# STM32H533 register map
File version: 1.3
CPU: CM33 r0p0, little endian, MPU, FPU, 4 interrupt priority bits
Registers are 32-bit, read-write, reset 0x0 unless marked. A register's access mark holds for its fields unless they carry their own. Offsets are from the block's base; [hi:lo] are bit positions; {n}, {i} and the like mark numbered series; 'fields as' and 'values as' point back to an identical list.

## RCC (part 2 of 2) — RCC address block description
Base 0x44020C00
Same registers: RCC_S 0x54020C00
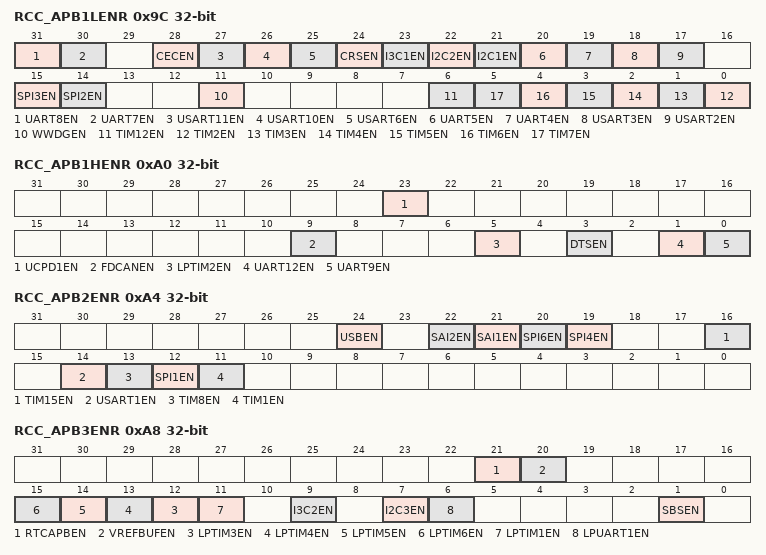
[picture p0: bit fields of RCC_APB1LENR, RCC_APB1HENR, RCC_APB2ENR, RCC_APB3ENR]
0x9C RCC_APB1LENR — RCC APB1 peripheral clock register
  [31] UART8EN — UART8 clock enable
    0=UART8 peripheral clock disabled (default after reset); 1=UART8 peripheral clock enabled
  [30] UART7EN — UART7 clock enable
    0=UART7 peripheral clock disabled (default after reset); 1=UART7 peripheral clock enabled
  [28] CECEN — HDMI-CEC clock enable
    0=HDMI-CEC peripheral clock disabled (default after reset); 1=HDMI-CEC peripheral clock enabled
  [27] USART11EN — USART11 clock enable
    0=USART11 peripheral clock disabled (default after reset); 1=USART11 peripheral clock enabled
  [26] USART10EN — USART10 clock enable
    0=USART10 peripheral clock disabled (default after reset); 1=USART10 peripheral clock enabled
  [25] USART6EN — USART6 clock enable
    0=USART6 peripheral clock disabled (default after reset); 1=USART6 peripheral clock enabled
  [24] CRSEN — CRS clock enable
    0=CRS peripheral clock disabled (default after reset); 1=CRS peripheral clock enabled
  [23] I3C1EN — I3C1 clock enable
    0=I3C1 peripheral clock disabled (default after reset); 1=I3C1 peripheral clock enabled
  [22] I2C2EN — I2C2 clock enable
    0=I2C2 peripheral clock disabled (default after reset); 1=I2C2 peripheral clock enabled
  [21] I2C1EN — I2C1 clock enable
    0=I2C1 peripheral clock disabled (default after reset); 1=I2C1 peripheral clock enabled
  [20] UART5EN — UART5 clock enable
    0=UART5 peripheral clock disabled (default after reset); 1=UART5 peripheral clock enabled
  [19] UART4EN — UART4 clock enable
    0=UART4 peripheral clock disabled (default after reset); 1=UART4 peripheral clock enabled
  [18] USART3EN — USART3 clock enable
    0=USART3 peripheral clock disabled (default after reset); 1=USART3 peripheral clock enabled
  [17] USART2EN — USART2 clock enable
    0=USART2 peripheral clock disabled (default after reset); 1=USART2 peripheral clock enabled
  [15] SPI3EN — SPI3 clock enable
    0=SPI3 peripheral clock disabled (default after reset); 1=SPI3 peripheral clock enabled
  [14] SPI2EN — SPI2 clock enable
    0=SPI2 peripheral clock disabled (default after reset); 1=SPI2 peripheral clock enabled
  [11] WWDGEN — WWDG clock enable
    0=WWDG peripheral clock disabled (default after reset); 1=WWDG peripheral clock enabled
  [6] TIM12EN — TIM12 clock enable
    0=TIM12 peripheral clock disabled (default after reset); 1=TIM12 peripheral clock enabled
  [n-2] TIM{n}EN (n=2..7) — TIM{n} clock enable
    0=TIM{n} peripheral clock disabled (default after reset); 1=TIM{n} peripheral clock enabled
0xA0 RCC_APB1HENR — RCC APB1 peripheral clock register
  [23] UCPD1EN — UCPD1 clock enable
    0=UCPD peripheral clock disabled (default after reset); 1=UCPD peripheral clock enabled
  [9] FDCANEN — FDCAN1 and FDCAN2 peripheral clock enable
    0=FDCAN1 and FDCAN2 peripheral clock disabled (default after reset); 1=FDCAN1 and FDCAN2 peripheral clock enabled
  [5] LPTIM2EN — LPTIM2 clock enable
    0=LPTIM2 peripheral clock disabled (default after reset); 1=LPTIM2 peripheral clock enabled
  [3] DTSEN — DTS clock enable
    0=DTS peripheral clock disabled (default after reset); 1=DTS peripheral clock enabled
  [1] UART12EN — UART12 clock enable
    0=UART12 peripheral clock disabled (default after reset); 1=UART12 peripheral clock enabled
  [0] UART9EN — UART9 clock enable
    0=UART9 peripheral clock disabled (default after reset); 1=resets UART9 peripheral clock enabled
0xA4 RCC_APB2ENR — RCC APB2 peripheral clock register
  [24] USBEN — USB clock enable
    0=USB peripheral clock disabled (default after reset); 1=USB peripheral clock enabled
  [22] SAI2EN — SAI2 clock enable
    0=SAI2 clock disabled; 1=SAI2 clock enabled
  [21] SAI1EN — SAI1 clock enable
    0=SAI1 peripheral clock disabled (default after reset); 1=SAI1 peripheral clock enabled
  [20] SPI6EN — SPI6 clock enable
    0=SPI6 peripheral clock disabled (default after reset); 1=SPI6 peripheral clock enabled
  [19] SPI4EN — SPI4 clock enable
    0=SPI4 peripheral clock disabled (default after reset); 1=SPI4 peripheral clock enabled
  [16] TIM15EN — TIM15 clock enable
    0=TIM15 peripheral clock disabled (default after reset); 1=TIM15 peripheral clock enabled
  [14] USART1EN — USART1 clock enable
    0=USART1 peripheral clock disabled (default after reset); 1=USART1 peripheral clock enabled
  [13] TIM8EN — TIM8 clock enable
    0=TIM8 peripheral clock disabled (default after reset); 1=TIM8 peripheral clock enabled
  [12] SPI1EN — SPI1 clock enable
    0=SPI1 peripheral clock disabled (default after reset); 1=SPI1 peripheral clock enabled
  [11] TIM1EN — TIM1 clock enable
    0=TIM1 peripheral clock disabled (default after reset); 1=TIM1 peripheral clock enabled
0xA8 RCC_APB3ENR — RCC APB3 peripheral clock register
  [21] RTCAPBEN — RTC APB interface clock enable
    0=RTC APB interface clock disabled (default after reset); 1=RTC APB interface clock enabled
  [20] VREFBUFEN — VREFBUF clock enable
    0=VREFBUF peripheral clock disabled (default after reset); 1=VREFBUF peripheral clock enabled
  [n+9] LPTIM{n}EN (n=3..6) — LPTIM{n} clock enable
    0=LPTIM{n} peripheral clock disabled (default after reset); 1=LPTIM{n} peripheral clock enabled
  [11] LPTIM1EN — LPTIM1 clock enable
    0=LPTIM1 peripheral clock disabled (default after reset); 1=LPTIM1 peripheral clock enabled
  [9] I3C2EN — I3C2 clock enable
    0=I3C2 peripheral clock disabled (default after reset); 1=I3C2 peripheral clock enabled
  [7] I2C3EN — I2C3 clock enable
    0=I2C3 peripheral clock disabled (default after reset); 1=I2C3 peripheral clock enabled
  [6] LPUART1EN — LPUART1 clock enable
    0=LPUART1 peripheral clock disabled (default after reset); 1=LPUART1 peripheral clock enabled
  [1] SBSEN — SBS clock enable
    0=SBS peripheral clock disabled (default after reset); 1=SBS peripheral clock enabled
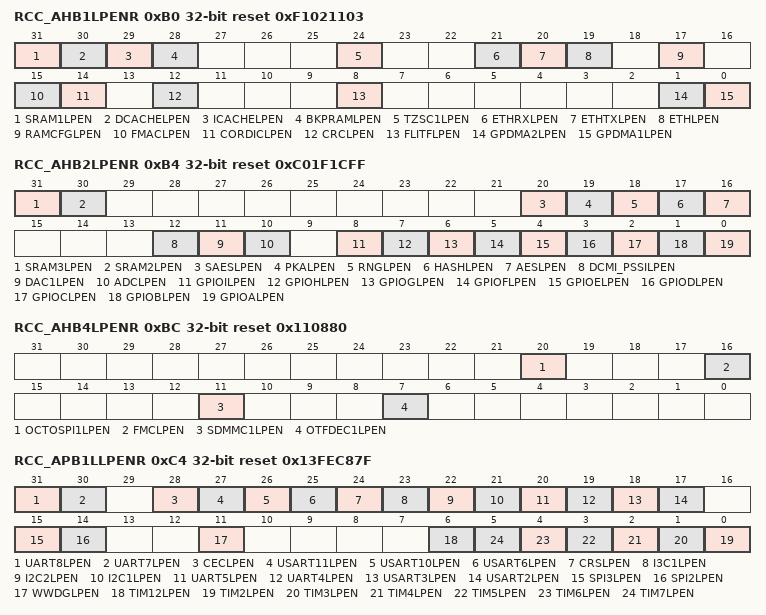
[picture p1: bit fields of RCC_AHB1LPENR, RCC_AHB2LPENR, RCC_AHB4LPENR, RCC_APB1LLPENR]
0xB0 RCC_AHB1LPENR reset 0xF1021103 — RCC AHB1 sleep clock register
  [31] SRAM1LPEN — SRAM1 clock enable during Sleep mode
    0=SRAM1 peripheral clock disabled during Sleep mode; 1=SRAM1 peripheral clock enabled during Sleep mode (default after reset)
  [30] DCACHELPEN — DCACHE clock enable during Sleep mode
    0=DCACHE peripheral clock disabled during Sleep mode; 1=DCACHE peripheral clock enabled during Sleep mode (default after reset)
  [29] ICACHELPEN — ICACHE clock enable during Sleep mode
    0=ICACHE peripheral clock disabled during Sleep mode; 1=ICACHE peripheral clock enabled during Sleep mode (default after reset)
  [28] BKPRAMLPEN — BKPRAM clock enable during Sleep mode
    0=BKPRAM peripheral clock disabled during Sleep mode; 1=BKPRAM peripheral clock enabled during Sleep mode (default after reset)
  [24] TZSC1LPEN — TZSC1 clock enable during Sleep mode
    0=TZSC1 peripheral clock disabled during Sleep mode; 1=TZSC1 peripheral clock enabled during Sleep mode (default after reset)
  [21] ETHRXLPEN — ETHRX clock enable during Sleep mode
    0=ETHRX clock disabled during Sleep mode; 1=ETHRX clock enabled during Sleep mode (default after reset)
  [20] ETHTXLPEN — ETHTX clock enable during Sleep mode
    0=ETHTX clock disabled during Sleep mode; 1=ETHTX clock enabled during Sleep mode (default after reset)
  [19] ETHLPEN — ETH clock enable during Sleep mode
    0=ETH peripheral clock disabled during Sleep mode; 1=ETH peripheral clock enabled during Sleep mode (default after reset)
  [17] RAMCFGLPEN — RAMCFG clock enable during Sleep mode
    0=RAMCFG peripheral clock disabled during Sleep mode; 1=RAMCFG peripheral clock enabled during Sleep mode (default after reset)
  [15] FMACLPEN — FMAC clock enable during Sleep mode
    0=FMAC peripheral clock disabled during Sleep mode; 1=FMAC peripheral clock enabled during Sleep mode (default after reset)
  [14] CORDICLPEN — CORDIC clock enable during Sleep mode
    0=CORDIC peripheral clock disabled during Sleep mode; 1=CORDIC peripheral clock enabled during Sleep mode (default after reset)
  [12] CRCLPEN — CRC clock enable during Sleep mode
    0=CRC peripheral clock disabled during Sleep mode; 1=CRC peripheral clock enabled during Sleep mode (default after reset)
  [8] FLITFLPEN — Flash interface (FLITF) clock enable during Sleep mode
    0=FLITF peripheral clock disabled during Sleep mode; 1=FLITF peripheral clock enabled during Sleep mode (default after reset)
  [1] GPDMA2LPEN — GPDMA2 clock enable during Sleep mode
    0=GPDMA2 peripheral clock disabled during Sleep mode; 1=GPDMA2 peripheral clock enabled during Sleep mode (default after reset)
  [0] GPDMA1LPEN — GPDMA1 clock enable during Sleep mode
    0=GPDMA1 peripheral clock disabled during Sleep mode; 1=GPDMA1 peripheral clock enabled during Sleep mode (default after reset)
0xB4 RCC_AHB2LPENR reset 0xC01F1CFF — RCC AHB2 sleep clock register
  [31] SRAM3LPEN — SRAM3 clock enable during Sleep mode
    0=SRAM3 peripheral clock disabled during Sleep mode; 1=SRAM3 peripheral clock enabled during Sleep mode (default after reset)
  [30] SRAM2LPEN — SRAM2 clock enable during Sleep mode
    0=SRAM2 peripheral clock disabled during Sleep mode; 1=SRAM2 peripheral clock enabled during Sleep mode (default after reset)
  [20] SAESLPEN — SAES clock enable during Sleep mode
    0=SAES peripheral clock disabled during Sleep mode; 1=SAES peripheral clock enabled during Sleep mode (default after reset)
  [19] PKALPEN — PKA clock enable during Sleep mode
    0=PKA peripheral clock disabled during Sleep mode; 1=PKA peripheral clock enabled during Sleep mode (default after reset)
  [18] RNGLPEN — RNG clock enable during Sleep mode
    0=RNG peripheral clock disabled during Sleep mode; 1=RNG peripheral clock enabled during Sleep mode (default after reset)
  [17] HASHLPEN — HASH clock enable during Sleep mode
    0=HASH peripheral clock disabled during Sleep mode; 1=HASH peripheral clock enabled during Sleep mode (default after reset)
  [16] AESLPEN — AES clock enable during Sleep mode
    0=AES peripheral clock disabled during Sleep mode; 1=AES peripheral clock enabled during Sleep mode (default after reset)
  [12] DCMI_PSSILPEN — digital camera interface clock enable during Sleep mode (DCMI or PSSI depending which interface is active)
    0=DCMI/PSSI peripheral clock disabled during Sleep mode; 1=DCMI/PSSI peripheral clock enabled during Sleep mode (default after reset)
  [11] DAC1LPEN — DAC clock enable during Sleep mode
    0=DAC peripheral clock disabled during Sleep mode; 1=DAC peripheral clock enabled during Sleep mode (default after reset)
  [10] ADCLPEN — ADC1 and 2 peripherals clock enable during Sleep mode
    0=ADC1 and 2 peripherals clock disabled during Sleep mode; 1=ADC1 and 2 peripherals clock enabled during Sleep mode (default after reset)
  [8] GPIOILPEN — GPIOI clock enable during Sleep mode
    0=GPIOI peripheral clock disabled during Sleep mode; 1=GPIOI peripheral clock enabled during Sleep mode (default after reset)
  [7] GPIOHLPEN — GPIOH clock enable during Sleep mode
    0=GPIOH peripheral clock disabled during Sleep mode; 1=GPIOH peripheral clock enabled during Sleep mode (default after reset)
  [6] GPIOGLPEN — GPIOG clock enable during Sleep mode
    0=GPIOG peripheral clock disabled during Sleep mode; 1=GPIOG peripheral clock enabled during Sleep mode (default after reset)
  [5] GPIOFLPEN — GPIOF clock enable during Sleep mode
    0=GPIOF peripheral clock disabled during Sleep mode; 1=GPIOF peripheral clock enabled during Sleep mode (default after reset)
  [4] GPIOELPEN — GPIOE clock enable during Sleep mode
    0=GPIOE peripheral clock disabled during Sleep mode; 1=GPIOE peripheral clock enabled during Sleep mode (default after reset)
  [3] GPIODLPEN — GPIOD clock enable during Sleep mode
    0=GPIOD peripheral clock disabled during Sleep mode; 1=GPIOD peripheral clock enabled during Sleep mode (default after reset)
  [2] GPIOCLPEN — GPIOC clock enable during Sleep mode
    0=GPIOC peripheral clock disabled during Sleep mode; 1=GPIOC peripheral clock enabled during Sleep mode (default after reset)
  [1] GPIOBLPEN — GPIOB clock enable during Sleep mode
    0=GPIOB peripheral clock disabled during Sleep mode; 1=GPIOB peripheral clock enabled during Sleep mode (default after reset)
  [0] GPIOALPEN — GPIOA clock enable during Sleep mode
    0=GPIOA peripheral clock disabled during Sleep mode; 1=GPIOA peripheral clock enabled during Sleep mode (default after reset)
0xBC RCC_AHB4LPENR reset 0x110880 — RCC AHB4 sleep clock register
  [20] OCTOSPI1LPEN — OCTOSPI1 clock enable during Sleep mode
    0=OCTOSPI1 peripheral clock disabled during Sleep mode; 1=OCTOSPI1 peripheral clock enabled during Sleep mode (default after reset)
  [16] FMCLPEN — FMC clock enable during Sleep mode
    0=FMC peripheral clock disabled during Sleep mode; 1=FMC peripheral clock enabled during Sleep mode (default after reset)
  [11] SDMMC1LPEN — SDMMC1 and SDMMC1 delay peripheral clock enable during Sleep mode
    0=SDMMC1 and SDMMC1 delay peripherals clock disabled during Sleep mode; 1=SDMMC1 and SDMMC1 delay peripherals clock enabled during Sleep mode (default after reset)
  [7] OTFDEC1LPEN — OTFDEC1 clock enable during Sleep mode
    0=OTFDEC1 peripheral clock disabled during Sleep mode; 1=OTFDEC1 peripheral clock enabled during Sleep mode (default after reset)
0xC4 RCC_APB1LLPENR reset 0x13FEC87F — RCC APB1 sleep clock register
  [31] UART8LPEN — UART8 clock enable during Sleep mode
    0=UART8 peripheral clock disabled during Sleep mode; 1=UART8 peripheral clock enabled during Sleep mode (default after reset)
  [30] UART7LPEN — UART7 clock enable during Sleep mode
    0=UART7 peripheral clock disabled during Sleep mode; 1=UART7 peripheral clock enabled during Sleep mode (default after reset)
  [28] CECLPEN — HDMI-CEC clock enable during Sleep mode
    0=HDMI-CEC peripheral clock disabled during Sleep mode; 1=HDMI-CEC peripheral clock enabled during Sleep mode (default after reset)
  [27] USART11LPEN — USART11 clock enable during Sleep mode
    0=USART11 peripheral clock disabled during Sleep mode; 1=USART11 peripheral clock enabled during Sleep mode (default after reset)
  [26] USART10LPEN — USART10 clock enable during Sleep mode
    0=USART10 peripheral clock disabled during Sleep mode; 1=USART10 peripheral clock enabled during Sleep mode (default after reset)
  [25] USART6LPEN — USART6 clock enable during Sleep mode
    0=USART6 peripheral clock disabled during Sleep mode; 1=USART6 peripheral clock enabled during Sleep mode (default after reset)
  [24] CRSLPEN — CRS clock enable during Sleep mode
    0=CRS peripheral clock disabled during Sleep mode; 1=CRS peripheral clock enabled during Sleep mode (default after reset)
  [23] I3C1LPEN — I3C1 clock enable during Sleep mode
    0=I3C1 peripheral clock disabled during Sleep mode; 1=I3C1 peripheral clock enabled during Sleep mode (default after reset)
  [22] I2C2LPEN — I2C2 clock enable during Sleep mode
    0=I2C2 peripheral clock disabled during Sleep mode; 1=I2C2 peripheral clock enabled during Sleep mode (default after reset)
  [21] I2C1LPEN — I2C1 clock enable during Sleep mode
    0=I2C1 peripheral clock disabled during Sleep mode; 1=I2C1 peripheral clock enabled during Sleep mode (default after reset)
  [20] UART5LPEN — UART5 clock enable during Sleep mode
    0=UART5 peripheral clock disabled during Sleep mode; 1=UART5 peripheral clock enabled during Sleep mode (default after reset)
  [19] UART4LPEN — UART4 clock enable during Sleep mode
    0=UART4 peripheral clock disabled during Sleep mode; 1=UART4 peripheral clock enabled during Sleep mode (default after reset)
  [18] USART3LPEN — USART3 clock enable during Sleep mode
    0=USART3 peripheral clock disabled during Sleep mode; 1=USART3 peripheral clock enabled during Sleep mode (default after reset)
  [17] USART2LPEN — USART2 clock enable during Sleep mode
    0=USART2 peripheral clock disabled during Sleep mode; 1=USART2 peripheral clock enabled during Sleep mode (default after reset)
  [15] SPI3LPEN — SPI3 clock enable during Sleep mode
    0=SPI3 peripheral clock disabled during Sleep mode; 1=SPI3 peripheral clock enabled during Sleep mode (default after reset)
  [14] SPI2LPEN — SPI2 clock enable during Sleep mode
    0=SPI2 peripheral clock disabled during Sleep mode; 1=SPI2 peripheral clock enabled during Sleep mode (default after reset)
  [11] WWDGLPEN — WWDG clock enable during Sleep mode
    0=WWDG peripheral clock disabled during Sleep mode; 1=WWDG peripheral clock enabled during Sleep mode (default after reset)
  [6] TIM12LPEN — TIM12 clock enable during Sleep mode
    0=TIM12 peripheral clock disabled during Sleep mode; 1=TIM12 peripheral clock enabled during Sleep mode (default after reset)
  [n-2] TIM{n}LPEN (n=2..7) — TIM{n} clock enable during Sleep mode
    0=TIM{n} peripheral clock disabled during Sleep mode; 1=TIM{n} peripheral clock enabled during Sleep mode (default after reset)
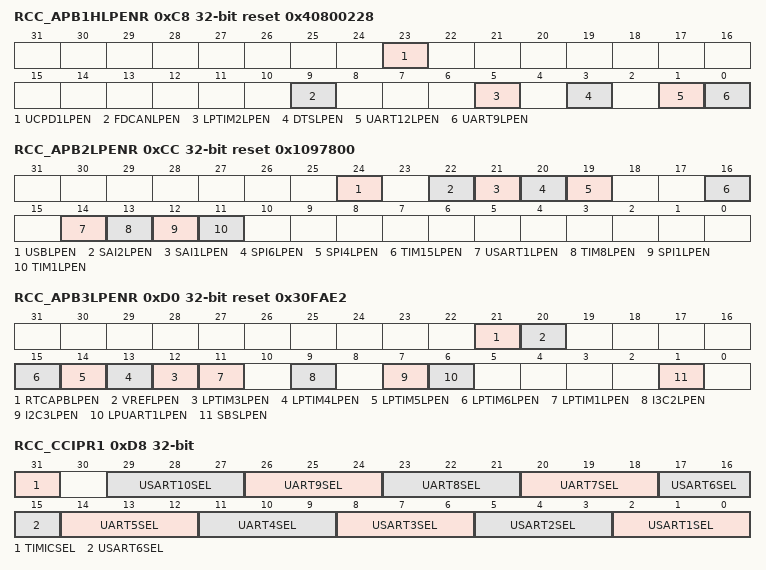
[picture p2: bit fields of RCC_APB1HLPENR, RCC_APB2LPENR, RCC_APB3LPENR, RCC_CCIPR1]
0xC8 RCC_APB1HLPENR reset 0x40800228 — RCC APB1 sleep clock register
  [23] UCPD1LPEN — UCPD1 clock enable during Sleep mode
    0=UCPD peripheral clock disabled during Sleep mode; 1=UCPD peripheral clock enabled during Sleep mode (default after reset)
  [9] FDCANLPEN — FDCAN1 and FDCAN2 peripheral clock enable during Sleep mode
    0=FDCAN1 and FDCAN2 peripheral clock disabled during Sleep mode; 1=FDCAN1 and FDCAN2 peripheral clock enabled during Sleep mode (default after reset)
  [5] LPTIM2LPEN — LPTIM2 clock enable during Sleep mode
    0=LPTIM2 peripheral clock disabled during Sleep mode; 1=LPTIM2 peripheral clock enabled during Sleep mode (default after reset)
  [3] DTSLPEN — DTS clock enable during Sleep mode
    0=DTS peripheral clock disabled during Sleep mode; 1=DTS peripheral clock enabled during Sleep mode (default after reset)
  [1] UART12LPEN — UART12 clock enable during Sleep mode
    0=UART12 peripheral clock disabled during Sleep mode; 1=UART12 peripheral clock enabled during Sleep mode (default after reset)
  [0] UART9LPEN — UART9 clock enable during Sleep mode
    0=UART9 peripheral clock disabled during Sleep mode; 1=resets UART9 peripheral clock enabled during Sleep mode (default after reset)
0xCC RCC_APB2LPENR reset 0x1097800 — RCC APB2 sleep clock register
  [24] USBLPEN — USB clock enable during Sleep mode
    0=USB peripheral clock disabled during Sleep mode; 1=USB peripheral clock enabled during Sleep mode (default after reset)
  [22] SAI2LPEN — SAI2 clock enable during Sleep mode
    0=SAI2 peripheral clock disabled during Sleep mode; 1=SAI2 peripheral clock enabled during Sleep mode (default after reset)
  [21] SAI1LPEN — SAI1 clock enable during Sleep mode
    0=SAI1 peripheral clock disabled during Sleep mode; 1=SAI1 peripheral clock enabled during Sleep mode (default after reset)
  [20] SPI6LPEN — SPI6 clock enable during Sleep mode
    0=SPI6 peripheral clock disabled during Sleep mode; 1=SPI6 peripheral clock enabled during Sleep mode (default after reset)
  [19] SPI4LPEN — SPI4 clock enable during Sleep mode
    0=SPI4 peripheral clock disabled during Sleep mode; 1=SPI4 peripheral clock enabled during Sleep mode (default after reset)
  [16] TIM15LPEN — TIM15 clock enable during Sleep mode
    0=TIM15 peripheral clock disabled during Sleep mode; 1=TIM15 peripheral clock enabled during Sleep mode (default after reset)
  [14] USART1LPEN — USART1 clock enable during Sleep mode
    0=USART1 peripheral clock disabled during Sleep mode; 1=USART1 peripheral clock enabled during Sleep mode (default after reset)
  [13] TIM8LPEN — TIM8 clock enable during Sleep mode
    0=TIM8 peripheral clock disabled during Sleep mode; 1=TIM8 peripheral clock enabled during Sleep mode (default after reset)
  [12] SPI1LPEN — SPI1 clock enable during Sleep mode
    0=SPI1 peripheral clock disabled during Sleep mode; 1=SPI1 peripheral clock enabled during Sleep mode (default after reset)
  [11] TIM1LPEN — TIM1 clock enable during Sleep mode
    0=TIM1 peripheral clock disabled during Sleep mode; 1=TIM1 peripheral clock enabled during Sleep mode (default after reset)
0xD0 RCC_APB3LPENR reset 0x30FAE2 — RCC APB3 sleep clock register
  [21] RTCAPBLPEN — RTC APB interface clock enable during Sleep mode
    0=RTC APB interface clock disabled during Sleep mode; 1=RTC APB interface clock enabled during Sleep mode (default after reset)
  [20] VREFLPEN — VREFBUF clock enable during Sleep mode
    0=VREFBUF peripheral clock disabled during Sleep mode; 1=VREFBUF peripheral clock enabled during Sleep mode (default after reset)
  [n+9] LPTIM{n}LPEN (n=3..6) — LPTIM{n} clock enable during Sleep mode
    0=LPTIM{n} peripheral clock disabled during Sleep mode; 1=LPTIM{n} peripheral clock enabled during Sleep mode (default after reset)
  [11] LPTIM1LPEN — LPTIM1 clock enable during Sleep mode
    0=LPTIM1 peripheral clock disabled during Sleep mode; 1=LPTIM1 peripheral clock enabled during Sleep mode (default after reset)
  [9] I3C2LPEN — I3C2 clock enable during Sleep mode
    0=I3C2 peripheral clock disabled during Sleep mode; 1=I3C2 peripheral clock enabled during Sleep mode (default after reset)
  [7] I2C3LPEN — I2C3 clock enable during Sleep mode
    0=I2C3 peripheral clock disabled during Sleep mode; 1=I2C3 peripheral clock enabled during Sleep mode (default after reset)
  [6] LPUART1LPEN — LPUART1 clock enable during Sleep mode
    0=LPUART1 peripheral clock disabled during Sleep mode; 1=LPUART1 peripheral clock enabled during Sleep mode (default after reset)
  [1] SBSLPEN — SBS clock enable during Sleep mode
    0=SBS peripheral clock disabled during Sleep mode; 1=SBS peripheral clock enabled during Sleep mode (default after reset)
0xD8 RCC_CCIPR1 — RCC kernel clock configuration register
  [31] TIMICSEL — TIM12, TIM15 and LPTIM2 input capture source selection
    0=No internal clock available for timers input capture (default after reset); 1=hsi_ker_ck/1024, hsi_ker_ck/8 and csi_ker_ck/128 selected for timers input capture
  [29:27] USART10SEL — USART10 kernel clock source selection
    0=rcc_pclk1 selected as kernel clock (default after reset); 1=pll2_q_ck selected as kernel clock; 2=pll3_q_ck selected as kernel clock; 3=hsi_ker_ck selected as kernel clock; 4=csi_ker_ck selected as kernel clock; 5=lse_ck selected as kernel clock
  [26:24] UART9SEL — UART9 kernel clock source selection
    values as USART10SEL
  [23:21] UART8SEL — UART8 kernel clock source selection
    values as USART10SEL
  [20:18] UART7SEL — UART7 kernel clock source selection
    values as USART10SEL
  [17:15] USART6SEL — USART6 kernel clock source selection
    values as USART10SEL
  [14:12] UART5SEL — UART5 kernel clock source selection
    values as USART10SEL
  [11:9] UART4SEL — UART4 kernel clock source selection
    values as USART10SEL
  [8:6] USART3SEL — USART3 kernel clock source selection
    values as USART10SEL
  [5:3] USART2SEL — USART2 kernel clock source selection
    values as USART10SEL
  [2:0] USART1SEL — USART1 kernel clock source selection
    0=rcc_pclk2 selected as kernel clock (default after reset); 1=pll2_q_ck selected as kernel clock; 2=pll3_q_ck selected as kernel clock; 3=hsi_ker_ck selected as kernel clock; 4=csi_ker_ck selected as kernel clock; 5=lse_ck selected as kernel clock
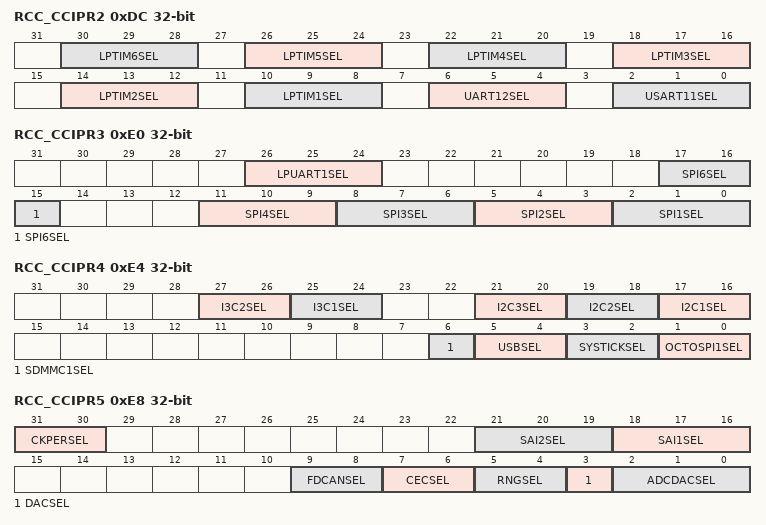
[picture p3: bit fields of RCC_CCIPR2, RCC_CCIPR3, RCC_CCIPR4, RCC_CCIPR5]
0xDC RCC_CCIPR2 — RCC kernel clock configuration register
  [4n+6:4n+4] LPTIM{n}SEL (n=3..6) — LPTIM{n} kernel clock source selection
    0=rcc_pclk3 selected as kernel clock (default after reset); 1=pll2_p_ck selected as kernel clock; 2=pll3_r_ck selected as kernel clock; 3=lse_ker_ck selected as kernel clock; 4=lsi_ker_ck selected as kernel clock; 5=per_ck selected as kernel clock
  [14:12] LPTIM2SEL — LPTIM2 kernel clock source selection
    0=rcc_pclk1 selected as kernel clock (default after reset); 1=pll2_p_ck selected as kernel clock; 2=pll3_r_ck selected as kernel clock; 3=lse_ker_ck selected as kernel clock; 4=lsi_ker_ck selected as kernel clock; 5=per_ck selected as kernel clock
  [10:8] LPTIM1SEL — LPTIM1 kernel clock source selection
    values as LPTIM3SEL
  [6:4] UART12SEL — UART12 kernel clock source selection
    values as RCC_CCIPR1.USART10SEL
  [2:0] USART11SEL — USART11 kernel clock source selection
    values as RCC_CCIPR1.USART10SEL
0xE0 RCC_CCIPR3 — RCC kernel clock configuration register
  [26:24] LPUART1SEL — LPUART1 kernel clock source selection
    0=rcc_pclk3 s elected as kernel clock (default after reset); 1=pll2_q_ck selected as kernel clock; 2=pll3_q_ck selected as kernel clock; 3=hsi_ker_ck selected as kernel clock; 4=csi_ker_ck selected as kernel clock; 5=lse_ck selected as kernel clock
  [17:15] SPI6SEL — SPI6 kernel clock source selection
    0=rcc_pclk2 selected as kernel clock (default after reset); 1=pll2_q_ck selected as kernel clock; 2=pll3_q_ck selected as kernel clock; 3=hsi_ker_ck selected as kernel clock; 4=csi_ker_ck selected as kernel clock; 5=hse_ck selected as kernel clock
  [11:9] SPI4SEL — SPI4 kernel clock source selection
    values as SPI6SEL
  [8:6] SPI3SEL — SPI3 kernel clock source selection
    0=pll1_q_ck selected as kernel clock (default after reset); 1=pll2_p_ck selected as kernel clock; 2=pll3_p_ck selected as kernel clock; 3=AUDIOCLK selected as kernel clock; 4=per_ck selected as kernel clock
  [5:3] SPI2SEL — SPI2 kernel clock source selection
    values as SPI3SEL
  [2:0] SPI1SEL — SPI1 kernel clock source selection
    values as SPI3SEL
0xE4 RCC_CCIPR4 — RCC kernel clock configuration register
  [27:26] I3C2SEL — I3C2 kernel clock source selection
    0=rcc_pclk1 selected as kernel clock (default after reset); 1=pll3_r_ck selected as kernel clock; 2=hsi_ker_ck selected as kernel clock; 3=no clock selected
  [25:24] I3C1SEL — I3C1 kernel clock source selection
    values as I3C2SEL
  [21:20] I2C3SEL — I2C3 kernel clock source selection
    0=rcc_pclk3 selected as kernel clock (default after reset); 1=pll3_r_ck selected as kernel clock; 2=hsi_ker_ck selected as kernel clock; 3=csi_ker_ck selected as kernel clock
  [19:18] I2C2SEL — I2C2 kernel clock source selection
    0=rcc_pclk1 selected as kernel clock (default after reset); 1=pll3_r_ck selected as kernel clock; 2=hsi_ker_ck selected as kernel clock; 3=csi_ker_ck selected as kernel clock
  [17:16] I2C1SEL — I2C1 kernel clock source selection
    values as I2C2SEL
  [6] SDMMC1SEL — SDMMC1 kernel clock source selection
    0=pll1_q_ck selected as kernel clock (default after reset); 1=pll2_r_ck selected as kernel clock
  [5:4] USBSEL — USB kernel clock source selection
    0=no clock is selected as kernel clock (default after reset); 1=pll1_q_ck selected as kernel clock; 2=pll3_q_ck selected as kernel clock; 3=hsi48_ker_ck selected as kernel clock
  [3:2] SYSTICKSEL — SYSTICK clock source selection
    0=rcc_hclk/8 selected as clock source (default after reset); 1=lsi_ker_ck[1] selected as clock source; 2=lse_ck[1] selected as clock source
  [1:0] OCTOSPI1SEL — OCTOSPI1 kernel clock source selection
    0=rcc_hclk4 selected as kernel clock (default after reset); 1=pll1_q_ck selected as kernel clock; 2=pll2_r_ck selected as kernel clock; 3=per_ck selected as kernel clock
0xE8 RCC_CCIPR5 — RCC kernel clock configuration register
  [31:30] CKPERSEL — per_ck clock source selection
    0=hsi_ker_ck selected as kernel clock (default after reset); 1=csi_ker_ck selected as kernel clock; 2=hse_ck selected as kernel clock
  [21:19] SAI2SEL — SAI2 kernel clock source selection
    values as RCC_CCIPR3.SPI3SEL
  [18:16] SAI1SEL — SAI1 kernel clock source selection
    values as RCC_CCIPR3.SPI3SEL
  [9:8] FDCANSEL — FDCAN1 and FDCAN2 kernel clock source selection
    0=hse_ck selected as kernel clock (default after reset); 1=pll1_q_ck selected as kernel clock; 2=pll2_q_ck selected as kernel clock
  [7:6] CECSEL — HSMI-CEC kernel clock source selection
    0=lse_ck selected as kernel clock (default after reset); 1=lsi_ker_ck selected as kernel clock; 2=csi_ker_ck/122 selected as kernel clock
  [5:4] RNGSEL — RNG kernel clock source selection
    0=hsi48_ker_ck selected as kernel clock (default after reset); 1=pll1_q_ck selected as kernel clock; 2=lse_ck selected as kernel clock; 3=lsi_ker_ck selected as kernel clock
  [3] DACSEL — DAC sample and hold clock
    0=dac_hold_ck selected as kernel clock (default after reset); 1=dac_hold_ck selected as kernel clock
  [2:0] ADCDACSEL — ADC and DAC kernel clock source selection
    0=rcc_hclk selected as kernel clock (default after reset); 1=sys_ck selected as kernel clock; 2=pll2_r_ck selected as kernel clock; 3=hse_ck selected as kernel clock; 4=hsi_ker_ck selected as kernel clock; 5=csi_ker_ck selected as kernel clock
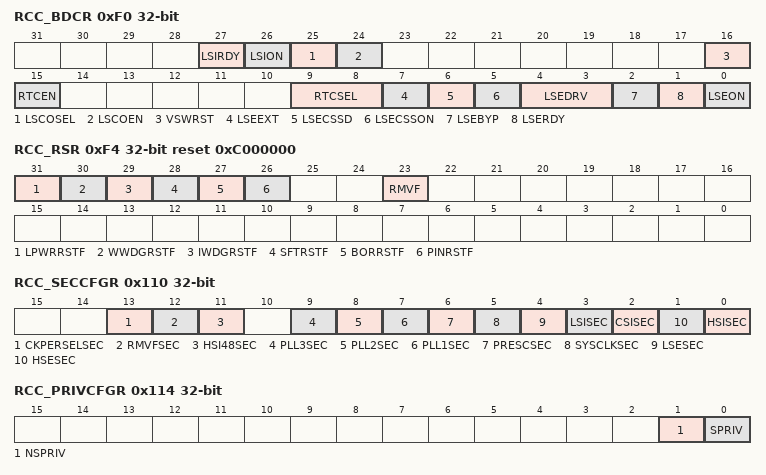
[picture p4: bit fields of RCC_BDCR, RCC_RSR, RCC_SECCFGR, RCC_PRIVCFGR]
0xF0 RCC_BDCR — RCC Backup domain control register
  [27] LSIRDY — LSI oscillator ready
    0=LSI oscillator not ready; 1=LSI oscillator ready
  [26] LSION — LSI oscillator enable
    0=LSI oscillator off; 1=LSI oscillator on
  [25] LSCOSEL — Low-speed clock output selection
    0=LSI clock selected; 1=LSE clock selected
  [24] LSCOEN — Low-speed clock output (LSCO) enable
    0=LSCO output disabled; 1=LSCO output enabled
  [16] VSWRST — VSwitch domain software reset
    0=reset not activated (default after Backup domain reset); 1=resets the entire VSW domain
  [15] RTCEN — RTC clock enable
    0=rtc_ck disabled (default after Backup domain reset); 1=rtc_ck enabled
  [9:8] RTCSEL — RTC clock source selection
    0=no clock (default after Backup domain reset); 1=LSE selected as RTC clock; 2=LSI selected as RTC clock; 3=HSE divided by RTCPRE value selected as RTC clock
  [7] LSEEXT — low-speed external clock type in bypass mode
    0=LSE in analog mode (default after Backup domain reset); 1=LSE in digital mode (do not use if RTC is active)
  [6] LSECSSD — LSE clock security system failure detection
    0=no failure detected on 32 kHz oscillator (default after Backup domain reset); 1=failure detected on 32 kHz oscillator
  [5] LSECSSON — LSE clock security system enable
    0=CSS on 32 kHz oscillator OFF (default after Backup domain reset); 1=CSS on 32 kHz oscillator ON
  [4:3] LSEDRV — LSE oscillator driving capability
    0=lowest drive (default after Backup domain reset); 1=medium-low drive; 2=medium-high drive; 3=highest drive
  [2] LSEBYP — LSE oscillator bypass
    0=LSE oscillator not bypassed (default after Backup domain reset); 1=LSE oscillator bypassed
  [1] LSERDY — LSE oscillator ready
    0=LSE oscillator not ready (default after Backup domain reset); 1=LSE oscillator ready
  [0] LSEON — LSE oscillator enabled
    0=LSE oscillator OFF (default after Backup domain reset); 1=LSE oscillator ON
0xF4 RCC_RSR reset 0xC000000 — RCC reset status register
  [31] LPWRRSTF — Low-power reset flag
    0=No illegal low-power mode reset occurred; 1=Illegal low-power mode reset occurred
  [30] WWDGRSTF — window watchdog reset flag
    0=no window watchdog reset occurred from WWDG (default after power-on reset); 1=window watchdog reset occurred from WWDG
  [29] IWDGRSTF — independent watchdog reset flag
    0=no independent watchdog reset occurred (default after power-on reset); 1=independent watchdog reset occurred
  [28] SFTRSTF — system reset from CPU reset flag
    0=no CPU software reset occurred (default after power-on reset); 1=a system reset has been generated by the CPU
  [27] BORRSTF — BOR reset flag
    0=no BOR reset occurred; 1=BOR reset occurred (default after power-on reset)
  [26] PINRSTF — pin reset flag (NRST)
    0=no reset from pin occurred; 1=reset from pin occurred (default after power-on reset)
  [23] RMVF — remove reset flag
    0=reset of the reset flags not activated (default after power-on reset); 1=resets the value of the reset flags
0x110 RCC_SECCFGR — RCC secure configuration register
  [all] fields
    0=non secure; 1=secure
  [13] CKPERSELSEC — per_ck selection security
  [12] RMVFSEC — Remove reset flag security
  [11] HSI48SEC — HSI48 clock configuration and status bits security
  [9] PLL3SEC — PLL3 clock configuration and status bits security
  [8] PLL2SEC — PLL2 clock configuration and status bits security
  [7] PLL1SEC — PLL1 clock configuration and status bits security
  [6] PRESCSEC — AHBx/APBx prescaler configuration bits security
  [5] SYSCLKSEC — SYSCLK clock selection, STOPWUCK bit, clock output on MCO configuration security
  [4] LSESEC — LSE clock configuration and status bits security
  [3] LSISEC — LSI clock configuration and status bits security
  [2] CSISEC — CSI clock configuration and status bits security
  [1] HSESEC — HSE clock configuration bits, status bits and HSE_CSS security
  [0] HSISEC — HSI clock configuration and status bits security
0x114 RCC_PRIVCFGR — RCC privilege configuration register
  [1] NSPRIV — RCC non-secure functions privilege configuration
    0=Read and write to RCC non-secure functions can be done by privileged or unprivileged access; 1=Read and write to RCC non-secure functions can be done by privileged access only
  [0] SPRIV — RCC secure functions privilege configuration
    0=Read and write to RCC secure functions can be done by privileged or unprivileged access; 1=Read and write to RCC secure functions can be done by privileged access only
